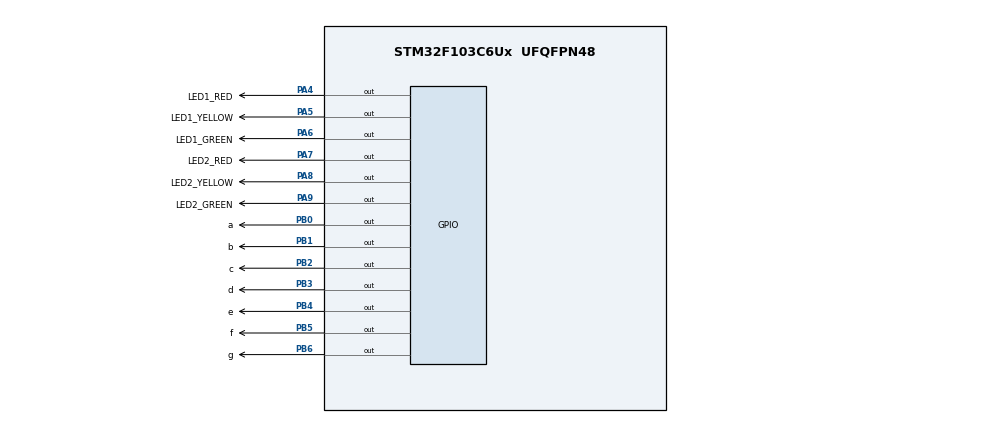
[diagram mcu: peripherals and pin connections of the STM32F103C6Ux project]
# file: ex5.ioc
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Mcu.Family=STM32F1
Mcu.Name=STM32F103C6Ux
Mcu.Package=UFQFPN48
NVIC.PriorityGroup=NVIC_PRIORITYGROUP_4
PA4.GPIO_Label=LED1_RED
PA4.Signal=GPIO_Output
PA5.GPIO_Label=LED1_YELLOW
PA5.Signal=GPIO_Output
PA6.GPIO_Label=LED1_GREEN
PA6.Signal=GPIO_Output
PA7.GPIO_Label=LED2_RED
PA7.Signal=GPIO_Output
PA8.GPIO_Label=LED2_YELLOW
PA8.Signal=GPIO_Output
PA9.GPIO_Label=LED2_GREEN
PA9.Signal=GPIO_Output
PB0.GPIO_Label=a
PB0.Signal=GPIO_Output
PB1.GPIO_Label=b
PB1.Signal=GPIO_Output
PB2.GPIO_Label=c
PB2.Signal=GPIO_Output
PB3.GPIO_Label=d
PB3.Signal=GPIO_Output
PB4.GPIO_Label=e
PB4.Signal=GPIO_Output
PB5.GPIO_Label=f
PB5.Signal=GPIO_Output
PB6.GPIO_Label=g
PB6.Signal=GPIO_Output
ProjectManager.HeapSize=0x200
ProjectManager.StackSize=0x400
ProjectManager.TargetToolchain=STM32CubeIDE
RCC.APB1Freq_Value=8000000
RCC.APB2Freq_Value=8000000
VP_SYS_VS_ND.Mode=No_Debug
board=custom

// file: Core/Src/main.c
/* USER CODE BEGIN Header */
/**
  ******************************************************************************
  * @file           : main.c
  * @brief          : Main program body
  ******************************************************************************
  * @attention
  *
  * <h2><center>&copy; Copyright (c) 2022 STMicroelectronics.
  * All rights reserved.</center></h2>
  *
  * This software component is licensed by ST under BSD 3-Clause license,
  * the "License"; You may not use this file except in compliance with the
  * License. You may obtain a copy of the License at:
  *                        opensource.org/licenses/BSD-3-Clause
  *
  ******************************************************************************
  */
/* USER CODE END Header */
#include "main.h"

void SystemClock_Config(void);
static void MX_GPIO_Init(void);

void display7SEG(int num){
//	if(num >= 10) num = 0 ;
	if(num == 0){
		HAL_GPIO_WritePin(a_GPIO_Port, a_Pin, RESET);
		HAL_GPIO_WritePin(b_GPIO_Port, b_Pin, RESET);
		HAL_GPIO_WritePin(c_GPIO_Port, c_Pin, RESET);
		HAL_GPIO_WritePin(d_GPIO_Port, d_Pin, RESET);
		HAL_GPIO_WritePin(e_GPIO_Port, e_Pin, RESET);
		HAL_GPIO_WritePin(f_GPIO_Port, f_Pin, RESET);
		HAL_GPIO_WritePin(g_GPIO_Port, g_Pin, SET);
	}else if(num == 1){
		HAL_GPIO_WritePin(a_GPIO_Port, a_Pin, SET);
		HAL_GPIO_WritePin(b_GPIO_Port, b_Pin, RESET);
		HAL_GPIO_WritePin(c_GPIO_Port, c_Pin, RESET);
		HAL_GPIO_WritePin(d_GPIO_Port, d_Pin, SET);
		HAL_GPIO_WritePin(e_GPIO_Port, e_Pin, SET);
		HAL_GPIO_WritePin(f_GPIO_Port, f_Pin, SET);
		HAL_GPIO_WritePin(g_GPIO_Port, g_Pin, SET);
	}else if(num == 2){
		HAL_GPIO_WritePin(a_GPIO_Port, a_Pin, RESET);
		HAL_GPIO_WritePin(b_GPIO_Port, b_Pin, RESET);
		HAL_GPIO_WritePin(c_GPIO_Port, c_Pin, SET);
		HAL_GPIO_WritePin(d_GPIO_Port, d_Pin, RESET);
		HAL_GPIO_WritePin(e_GPIO_Port, e_Pin, RESET);
		HAL_GPIO_WritePin(f_GPIO_Port, f_Pin, SET);
		HAL_GPIO_WritePin(g_GPIO_Port, g_Pin, RESET);
	}else if(num == 3){
		HAL_GPIO_WritePin(a_GPIO_Port, a_Pin, RESET);
		HAL_GPIO_WritePin(b_GPIO_Port, b_Pin, RESET);
		HAL_GPIO_WritePin(c_GPIO_Port, c_Pin, RESET);
		HAL_GPIO_WritePin(d_GPIO_Port, d_Pin, RESET);
		HAL_GPIO_WritePin(e_GPIO_Port, e_Pin, SET);
		HAL_GPIO_WritePin(f_GPIO_Port, f_Pin, SET);
		HAL_GPIO_WritePin(g_GPIO_Port, g_Pin, RESET);
	}else if( num == 4){
		HAL_GPIO_WritePin(a_GPIO_Port, a_Pin, SET);
		HAL_GPIO_WritePin(b_GPIO_Port, b_Pin, RESET);
		HAL_GPIO_WritePin(c_GPIO_Port, c_Pin, RESET);
		HAL_GPIO_WritePin(d_GPIO_Port, d_Pin, SET);
		HAL_GPIO_WritePin(e_GPIO_Port, e_Pin, SET);
		HAL_GPIO_WritePin(f_GPIO_Port, f_Pin, RESET);
		HAL_GPIO_WritePin(g_GPIO_Port, g_Pin, RESET);
	}else if(num == 5){
		HAL_GPIO_WritePin(a_GPIO_Port, a_Pin, RESET);
		HAL_GPIO_WritePin(b_GPIO_Port, b_Pin, SET);
		HAL_GPIO_WritePin(c_GPIO_Port, c_Pin, RESET);
		HAL_GPIO_WritePin(d_GPIO_Port, d_Pin, RESET);
		HAL_GPIO_WritePin(e_GPIO_Port, e_Pin, SET);
		HAL_GPIO_WritePin(f_GPIO_Port, f_Pin, RESET);
		HAL_GPIO_WritePin(g_GPIO_Port, g_Pin, RESET);
	}else if(num == 6){
		HAL_GPIO_WritePin(a_GPIO_Port, a_Pin, RESET);
		HAL_GPIO_WritePin(b_GPIO_Port, b_Pin, SET);
		HAL_GPIO_WritePin(c_GPIO_Port, c_Pin, RESET);
		HAL_GPIO_WritePin(d_GPIO_Port, d_Pin, RESET);
		HAL_GPIO_WritePin(e_GPIO_Port, e_Pin, RESET);
		HAL_GPIO_WritePin(f_GPIO_Port, f_Pin, RESET);
		HAL_GPIO_WritePin(g_GPIO_Port, g_Pin, RESET);
	}else if(num == 7){
		HAL_GPIO_WritePin(a_GPIO_Port, a_Pin, RESET);
		HAL_GPIO_WritePin(b_GPIO_Port, b_Pin, RESET);
		HAL_GPIO_WritePin(c_GPIO_Port, c_Pin, RESET);
		HAL_GPIO_WritePin(d_GPIO_Port, d_Pin, SET);
		HAL_GPIO_WritePin(e_GPIO_Port, e_Pin, SET);
		HAL_GPIO_WritePin(f_GPIO_Port, f_Pin, SET);
		HAL_GPIO_WritePin(g_GPIO_Port, g_Pin, SET);
	}else if (num == 8 ){
		HAL_GPIO_WritePin(a_GPIO_Port, a_Pin, RESET);
		HAL_GPIO_WritePin(b_GPIO_Port, b_Pin, RESET);
		HAL_GPIO_WritePin(c_GPIO_Port, c_Pin, RESET);
		HAL_GPIO_WritePin(d_GPIO_Port, d_Pin, RESET);
		HAL_GPIO_WritePin(e_GPIO_Port, e_Pin, RESET);
		HAL_GPIO_WritePin(f_GPIO_Port, f_Pin, RESET);
		HAL_GPIO_WritePin(g_GPIO_Port, g_Pin, RESET);
	}else{
		HAL_GPIO_WritePin(a_GPIO_Port, a_Pin, RESET);
		HAL_GPIO_WritePin(b_GPIO_Port, b_Pin, RESET);
		HAL_GPIO_WritePin(c_GPIO_Port, c_Pin, RESET);
		HAL_GPIO_WritePin(d_GPIO_Port, d_Pin, RESET);
		HAL_GPIO_WritePin(e_GPIO_Port, e_Pin, SET);
		HAL_GPIO_WritePin(f_GPIO_Port, f_Pin, RESET);
		HAL_GPIO_WritePin(g_GPIO_Port, g_Pin, RESET);
	}
}
int main(void)
{

  /* MCU Configuration--------------------------------------------------------*/

  /* Reset of all peripherals, Initializes the Flash interface and the Systick. */
  HAL_Init();

  /* Configure the system clock */
  SystemClock_Config();

  /* Initialize all configured peripherals */
  MX_GPIO_Init();

  /* Infinite loop */
  /* USER CODE BEGIN WHILE */
  int time = 0 ;
  while (1)
  {
    /* USER CODE END WHILE */
	  // 5s dau
	  if( time < 5 ){
		  	// bat den do 5s cua he thong 1
	  		  HAL_GPIO_WritePin(LED1_RED_GPIO_Port, LED1_RED_Pin, GPIO_PIN_RESET) ;
	  		  HAL_GPIO_WritePin(LED1_YELLOW_GPIO_Port, LED1_YELLOW_Pin, GPIO_PIN_SET) ;
	  		  HAL_GPIO_WritePin(LED1_GREEN_GPIO_Port, LED1_GREEN_Pin, GPIO_PIN_SET) ;
		  	//bat den vang cua he thong 2
	  		  if(time < 3){
	  		  		HAL_GPIO_WritePin(LED2_RED_GPIO_Port, LED2_RED_Pin, GPIO_PIN_SET) ;
	  		  		HAL_GPIO_WritePin(LED2_YELLOW_GPIO_Port, LED2_YELLOW_Pin, GPIO_PIN_SET) ;
	  		  		HAL_GPIO_WritePin(LED2_GREEN_GPIO_Port, LED2_GREEN_Pin, GPIO_PIN_RESET) ;
	  		  	    display7SEG(3 - time); // dem nguoc bang led7SEG
	  		  }
		  	 // bat den xanh cua he thong 2
		  	  else if(time >= 3 ){
	  		  		HAL_GPIO_WritePin(LED2_RED_GPIO_Port, LED2_RED_Pin, GPIO_PIN_SET) ;
	  		  		HAL_GPIO_WritePin(LED2_YELLOW_GPIO_Port, LED2_YELLOW_Pin, GPIO_PIN_RESET) ;
	  		  		HAL_GPIO_WritePin(LED2_GREEN_GPIO_Port, LED2_GREEN_Pin, GPIO_PIN_SET) ;
	  		  		display7SEG(5 - time);  // dem nguoc bang led7SEG
	  		  }
	  		  time++ ;
		  //5s sau
	  	  }else if(time >= 5 && time < 10){
		  	  // bat den do cua he thong 2
	  		  HAL_GPIO_WritePin(LED2_RED_GPIO_Port, LED2_RED_Pin, GPIO_PIN_RESET) ;
	  		  HAL_GPIO_WritePin(LED2_YELLOW_GPIO_Port, LED2_YELLOW_Pin, GPIO_PIN_SET) ;
	  		  HAL_GPIO_WritePin(LED2_GREEN_GPIO_Port, LED2_GREEN_Pin, GPIO_PIN_SET) ;
	  		  if(time < 8){
	  		  		HAL_GPIO_WritePin(LED1_RED_GPIO_Port, LED1_RED_Pin, GPIO_PIN_SET) ;
	  		  		HAL_GPIO_WritePin(LED1_YELLOW_GPIO_Port, LED1_YELLOW_Pin, GPIO_PIN_SET) ;
	  		  		HAL_GPIO_WritePin(LED1_GREEN_GPIO_Port, LED1_GREEN_Pin, GPIO_PIN_RESET) ;
	  		  	    display7SEG(10 - time);  // dem nguoc bang led7SEG
	  		  }else if(time >= 8 ){
	  		  		HAL_GPIO_WritePin(LED1_RED_GPIO_Port, LED1_RED_Pin, GPIO_PIN_SET) ;
	  		  		HAL_GPIO_WritePin(LED1_YELLOW_GPIO_Port, LED1_YELLOW_Pin, GPIO_PIN_RESET) ;
	  		  		HAL_GPIO_WritePin(LED1_GREEN_GPIO_Port, LED1_GREEN_Pin, GPIO_PIN_SET) ;
	  		  	    display7SEG(10 - time);  // dem nguoc bang led7SEG
	  		  		time++;
	  		  }
	  		  time++ ;
	  	  }else {
		  	//reset bien time
	  		display7SEG(1);
	  		time = 0 ;
	  	  }
	  	  HAL_Delay(1000) ;
  }
}

void SystemClock_Config(void)
{
  RCC_OscInitTypeDef RCC_OscInitStruct = {0};
  RCC_ClkInitTypeDef RCC_ClkInitStruct = {0};

  /** Initializes the RCC Oscillators according to the specified parameters
  * in the RCC_OscInitTypeDef structure.
  */
  RCC_OscInitStruct.OscillatorType = RCC_OSCILLATORTYPE_HSI;
  RCC_OscInitStruct.HSIState = RCC_HSI_ON;
  RCC_OscInitStruct.HSICalibrationValue = RCC_HSICALIBRATION_DEFAULT;
  RCC_OscInitStruct.PLL.PLLState = RCC_PLL_NONE;
  if (HAL_RCC_OscConfig(&RCC_OscInitStruct) != HAL_OK)
  {
    Error_Handler();
  }
  /** Initializes the CPU, AHB and APB buses clocks
  */
  RCC_ClkInitStruct.ClockType = RCC_CLOCKTYPE_HCLK|RCC_CLOCKTYPE_SYSCLK
                              |RCC_CLOCKTYPE_PCLK1|RCC_CLOCKTYPE_PCLK2;
  RCC_ClkInitStruct.SYSCLKSource = RCC_SYSCLKSOURCE_HSI;
  RCC_ClkInitStruct.AHBCLKDivider = RCC_SYSCLK_DIV1;
  RCC_ClkInitStruct.APB1CLKDivider = RCC_HCLK_DIV1;
  RCC_ClkInitStruct.APB2CLKDivider = RCC_HCLK_DIV1;

  if (HAL_RCC_ClockConfig(&RCC_ClkInitStruct, FLASH_LATENCY_0) != HAL_OK)
  {
    Error_Handler();
  }
}

static void MX_GPIO_Init(void)
{
  GPIO_InitTypeDef GPIO_InitStruct = {0};

  /* GPIO Ports Clock Enable */
  __HAL_RCC_GPIOA_CLK_ENABLE();
  __HAL_RCC_GPIOB_CLK_ENABLE();

  /*Configure GPIO pin Output Level */
  HAL_GPIO_WritePin(GPIOA, LED1_RED_Pin|LED1_YELLOW_Pin|LED1_GREEN_Pin|LED2_RED_Pin
                          |LED2_YELLOW_Pin|LED2_GREEN_Pin, GPIO_PIN_RESET);

  /*Configure GPIO pin Output Level */
  HAL_GPIO_WritePin(GPIOB, a_Pin|b_Pin|c_Pin|d_Pin
                          |e_Pin|f_Pin|g_Pin, GPIO_PIN_RESET);

  /*Configure GPIO pins : LED1_RED_Pin LED1_YELLOW_Pin LED1_GREEN_Pin LED2_RED_Pin
                           LED2_YELLOW_Pin LED2_GREEN_Pin */
  GPIO_InitStruct.Pin = LED1_RED_Pin|LED1_YELLOW_Pin|LED1_GREEN_Pin|LED2_RED_Pin
                          |LED2_YELLOW_Pin|LED2_GREEN_Pin;
  GPIO_InitStruct.Mode = GPIO_MODE_OUTPUT_PP;
  GPIO_InitStruct.Pull = GPIO_NOPULL;
  GPIO_InitStruct.Speed = GPIO_SPEED_FREQ_LOW;
  HAL_GPIO_Init(GPIOA, &GPIO_InitStruct);

  /*Configure GPIO pins : a_Pin b_Pin c_Pin d_Pin
                           e_Pin f_Pin g_Pin */
  GPIO_InitStruct.Pin = a_Pin|b_Pin|c_Pin|d_Pin
                          |e_Pin|f_Pin|g_Pin;
  GPIO_InitStruct.Mode = GPIO_MODE_OUTPUT_PP;
  GPIO_InitStruct.Pull = GPIO_NOPULL;
  GPIO_InitStruct.Speed = GPIO_SPEED_FREQ_LOW;
  HAL_GPIO_Init(GPIOB, &GPIO_InitStruct);

}

void Error_Handler(void)
{
  __disable_irq();
  while (1)
  {
  }
}

/************************ (C) COPYRIGHT STMicroelectronics *****END OF FILE****/
